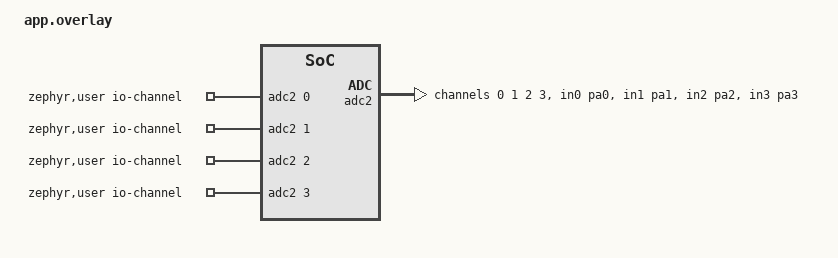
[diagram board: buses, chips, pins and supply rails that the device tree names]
/ {
	zephyr,user {
		io-channels = <&adc2 0>, <&adc2 1>, <&adc2 2>, <&adc2 3>;
	};
};

&adc1 {
	status = "disabled";
};

&adc2 {
	pinctrl-0 = <&adc2_in0_pa0 &adc2_in1_pa1 &adc2_in2_pa2 &adc2_in3_pa3>;
	pinctrl-names = "default";
	vref-mv = <3300>;
	status = "okay";
	#address-cells = <1>;
	#size-cells = <0>;

	channel@0 {
		reg = <0>;
		zephyr,gain = "ADC_GAIN_1";
		zephyr,reference = "ADC_REF_INTERNAL";
		zephyr,acquisition-time = <ADC_ACQ_TIME(ADC_ACQ_TIME_TICKS, 289)>;
		zephyr,resolution = <12>;
	};

	channel@1 {
		reg = <1>;
		zephyr,gain = "ADC_GAIN_1";
		zephyr,reference = "ADC_REF_INTERNAL";
		zephyr,acquisition-time = <ADC_ACQ_TIME(ADC_ACQ_TIME_TICKS, 289)>;
		zephyr,resolution = <12>;
	};

	channel@2 {
		reg = <2>;
		zephyr,gain = "ADC_GAIN_1";
		zephyr,reference = "ADC_REF_INTERNAL";
		zephyr,acquisition-time = <ADC_ACQ_TIME(ADC_ACQ_TIME_TICKS, 289)>;
		zephyr,resolution = <12>;
	};

	channel@3 {
		reg = <3>;
		zephyr,gain = "ADC_GAIN_1";
		zephyr,reference = "ADC_REF_INTERNAL";
		zephyr,acquisition-time = <ADC_ACQ_TIME(ADC_ACQ_TIME_TICKS, 289)>;
		zephyr,resolution = <12>;
	};
};
